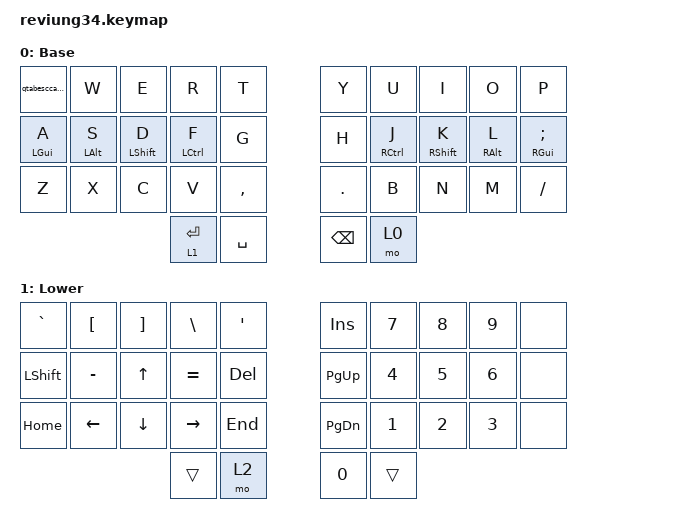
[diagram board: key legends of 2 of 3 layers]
/*
 * Copyright (c) 2023 The ZMK Contributors
 *
 * SPDX-License-Identifier: MIT
 */

#include <behaviors.dtsi>
#include <dt-bindings/zmk/bt.h>
#include <dt-bindings/zmk/keys.h>
#include <dt-bindings/zmk/outputs.h>

/ {
    chosen {
        // 34 keys.
        // zmk,matrix-transform = &dual_1u_transform;
        // 33 keys. Center two thumb keys replaced by a single 2u key. Remember to adjust your
        // keymap accordingly!

        zmk,matrix-transform = &single_2u_transform;
    };
};

/ {
    behaviors {
        holdtap: holdtap {
            compatible = "zmk,behavior-hold-tap";
            label = "HOLDTAP";
            bindings = <&kp>, <&kp>;

            #binding-cells = <2>;
            tapping-term-ms = <200>;
            hold-trigger-key-positions = <10 11 12 13 16 17 18 19>;
            flavor = "tap-preferred";
            quick-tap-ms = <150>;
        };

        qtabesccaps: qtabesccaps {
            compatible = "zmk,behavior-tap-dance";
            label = "QTABESCCAPS";
            #binding-cells = <0>;
            bindings = <&kp Q>, <&kp TAB>, <&kp ESCAPE>, <&kp CAPS>;
        };
    };

    keymap {
        compatible = "zmk,keymap";

        base {
            display-name = "Base";
            bindings = <
&qtabesccaps         &kp W                &kp E                  &kp R             &kp T        &kp Y          &kp U             &kp I                   &kp O                 &kp P
&holdtap LEFT_GUI A  &holdtap LEFT_ALT S  &holdtap LEFT_SHIFT D  &holdtap LCTRL F  &kp G        &kp H          &holdtap RCTRL J  &holdtap RIGHT_SHIFT K  &holdtap RIGHT_ALT L  &holdtap RIGHT_GUI SEMICOLON
&kp Z                &kp X                &kp C                  &kp V             &kp COMMA    &kp PERIOD     &kp B             &kp N                   &kp M                 &kp SLASH
                                                                 &lt 1 ENTER       &kp SPACE    &kp BACKSPACE  &mo 0
            >;
        };

        lower {
            display-name = "Lower";
            bindings = <
&kp GRAVE  &kp LBKT        &kp RBKT        &kp BSLH   &kp APOS    &kp INS        &kp NUMBER_7  &kp NUMBER_8  &kp N9        &none
&kp LSHFT  &kp MINUS       &kp UP_ARROW    &kp EQUAL  &kp DEL     &kp PAGE_UP    &kp NUMBER_4  &kp NUMBER_5  &kp NUMBER_6  &none
&kp HOME   &kp LEFT_ARROW  &kp DOWN_ARROW  &kp RIGHT  &kp END     &kp PAGE_DOWN  &kp NUMBER_1  &kp NUMBER_2  &kp NUMBER_3  &none
                                           &trans     &mo 2       &kp N0         &trans
            >;
        };

        layer_2 {
            bindings = <
&bt BT_DISC 0  &bt BT_DISC 1   &bt BT_DISC 2  &bt BT_DISC 3     &bt BT_DISC 4    &kp C_VOLUME_UP    &kp F1  &kp F2   &kp F3   &kp F4
&out OUT_TOG   &kp C_PREVIOUS  &kp C_NEXT     &kp C_PLAY_PAUSE  &bt BT_CLR       &kp C_MUTE         &kp F5  &kp F6   &kp F7   &kp F8
&bt BT_SEL 0   &bt BT_SEL 1    &bt BT_SEL 2   &bt BT_SEL 3      &bt BT_SEL 4     &kp C_VOLUME_DOWN  &kp F9  &kp F10  &kp F11  &kp F12
                                              &trans            &trans           &soft_off
            >;
        };
    };
};
